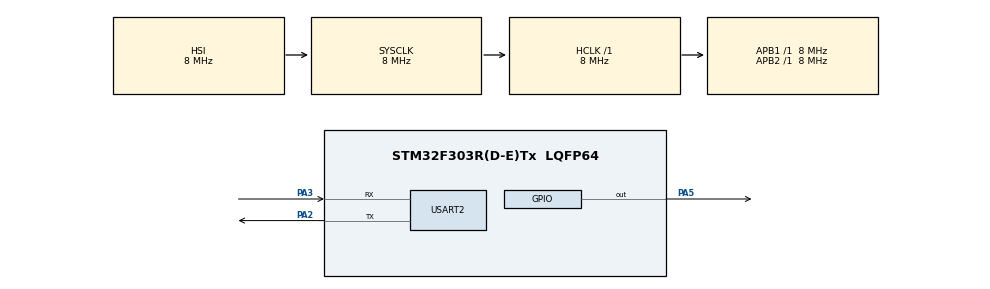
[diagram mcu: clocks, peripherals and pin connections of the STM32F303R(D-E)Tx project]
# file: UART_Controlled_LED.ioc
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Mcu.Family=STM32F3
Mcu.Name=STM32F303R(D-E)Tx
Mcu.Package=LQFP64
NVIC.PriorityGroup=NVIC_PRIORITYGROUP_4
NVIC.USART2_IRQn=true\:0\:0\:false\:false\:true\:true\:true\:true
PA2.Mode=Asynchronous
PA2.Signal=USART2_TX
PA3.Mode=Asynchronous
PA3.Signal=USART2_RX
PA5.Signal=GPIO_Output
ProjectManager.HeapSize=0x200
ProjectManager.StackSize=0x400
ProjectManager.TargetToolchain=STM32CubeIDE
RCC.AHBFreq_Value=8000000
RCC.APB1Freq_Value=8000000
RCC.APB2Freq_Value=8000000
RCC.CortexFreq_Value=8000000
RCC.HSE_VALUE=8000000
RCC.HSI_VALUE=8000000
RCC.LSE_VALUE=32768
RCC.SYSCLKFreq_VALUE=8000000
RCC.USBFreq_Value=16000000
USART2.VirtualMode-Asynchronous=VM_ASYNC
board=custom

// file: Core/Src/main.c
/* USER CODE BEGIN Header */
/**
  ******************************************************************************
  * @file           : main.c
  * @brief          : Main program body
  ******************************************************************************
  * @attention
  *
  * Copyright (c) 2025 STMicroelectronics.
  * All rights reserved.
  *
  * This software is licensed under terms that can be found in the LICENSE file
  * in the root directory of this software component.
  * If no LICENSE file comes with this software, it is provided AS-IS.
  *
  ******************************************************************************
  */
/* USER CODE END Header */
#include "main.h"

/* USER CODE BEGIN Includes */
#include "stdio.h"
#include <string.h>
#include <stdbool.h>
/* USER CODE END Includes */

UART_HandleTypeDef huart2;

void SystemClock_Config(void);
static void MX_GPIO_Init(void);
static void MX_USART2_UART_Init(void);

/* USER CODE BEGIN 0 */
/*volatile uint8_t RxByte = 0;
volatile uint8_t RxBuffer[3];
volatile uint8_t indx = 0;
volatile uint8_t command_ready = 0;
void HAL_UART_RxCpltCallback(UART_HandleTypeDef *huart)
{

	if (huart->Instance == USART2)
	    {
	        RxBuffer[indx++] = RxByte;

	        if (RxByte == '\n' || RxByte == '\r'|| indx >= sizeof(RxBuffer))
	        {
	            HAL_UART_Transmit(&huart2, (uint8_t *)RxBuffer, indx, HAL_MAX_DELAY);
	            indx = 0;
	            command_ready=1;
	        }
	        HAL_UART_Receive_IT(&huart2, (uint8_t *)&RxByte, 1);
	    }
}*/
#define RX_BUFFER_SIZE 10
char rxBuffer[RX_BUFFER_SIZE];
int rxIndex = 0;
char *msg;
/* USER CODE END 0 */

int main(void)
{

  /* MCU Configuration--------------------------------------------------------*/

  /* Reset of all peripherals, Initializes the Flash interface and the Systick. */
  HAL_Init();

  /* Configure the system clock */
  SystemClock_Config();

  /* Initialize all configured peripherals */
  MX_GPIO_Init();
  MX_USART2_UART_Init();
  /* USER CODE BEGIN 2 */
  /*printf("Enter the command to turn on LED on or off:\n");
  HAL_UART_Receive_IT(&huart2, (uint8_t *)&RxByte, 1);*/

    /* USER CODE END 2 */

  /* Infinite loop */
  while (1)
  {
	    /*if (command_ready)
	    {
	        HAL_UART_Transmit(&huart2, (uint8_t *)"\nCMD: ", 6, HAL_MAX_DELAY);
	        HAL_UART_Transmit(&huart2, (uint8_t *)RxBuffer, strlen((char*)RxBuffer), HAL_MAX_DELAY);
	        HAL_UART_Transmit(&huart2, (uint8_t *)"\r\n", 2, HAL_MAX_DELAY);
	      if (strcmp((char *)RxBuffer, "on") == 0)
	      {
	        HAL_GPIO_WritePin(GPIOA, GPIO_PIN_5, GPIO_PIN_SET);
	        char *msg = "LED turned ON\r\n";
	        HAL_UART_Transmit(&huart2, (uint8_t *)msg, strlen(msg), HAL_MAX_DELAY);
	      }
	      else if (strcmp((char *)RxBuffer, "off") == 0)
	      {
	        HAL_GPIO_WritePin(GPIOA, GPIO_PIN_5, GPIO_PIN_RESET);
	        char *msg = "LED turned OFF\r\n";
	        HAL_UART_Transmit(&huart2, (uint8_t *)msg, strlen(msg), HAL_MAX_DELAY);
	      }
	      else
	      {
	        char *msg = "Invalid command\r\n";
	        HAL_UART_Transmit(&huart2, (uint8_t *)msg, strlen(msg), HAL_MAX_DELAY);
	      }

	      command_ready = 0;  // reset flag after processing
	    }*/
	  uint8_t received_char;
	      // Receive one byte at a time (blocking)
	      HAL_UART_Receive(&huart2, &received_char, 1, HAL_MAX_DELAY);

	      if (received_char == '\r' || received_char == '\n')
	      {
	          rxBuffer[rxIndex] = '\0';  // Null-terminate the string
	          rxIndex = 0;               // Reset index for next command

	          if (strcmp(rxBuffer, "on") == 0)
	          {
	              HAL_GPIO_WritePin(GPIOA, GPIO_PIN_5, GPIO_PIN_SET);
	              msg = "LED turned ON\r\n";
	          }
	          else if (strcmp(rxBuffer, "off") == 0)
	          {
	              HAL_GPIO_WritePin(GPIOA, GPIO_PIN_5, GPIO_PIN_RESET);
	              msg = "LED turned OFF\r\n";
	          }
	          else
	          {
	              msg = "Invalid command. Type 'on' or 'off'.\r\n";
	          }

	          HAL_UART_Transmit(&huart2, (uint8_t*)msg, strlen(msg), HAL_MAX_DELAY);
	      }
	      else
	      {
	          if (rxIndex < RX_BUFFER_SIZE - 1)
	          {
	              rxBuffer[rxIndex++] = received_char;
	          }
	          // else: input too long, could reset rxIndex or handle error
	      }
  }
}

void SystemClock_Config(void)
{
  RCC_OscInitTypeDef RCC_OscInitStruct = {0};
  RCC_ClkInitTypeDef RCC_ClkInitStruct = {0};
  RCC_PeriphCLKInitTypeDef PeriphClkInit = {0};

  /** Initializes the RCC Oscillators according to the specified parameters
  * in the RCC_OscInitTypeDef structure.
  */
  RCC_OscInitStruct.OscillatorType = RCC_OSCILLATORTYPE_HSI;
  RCC_OscInitStruct.HSIState = RCC_HSI_ON;
  RCC_OscInitStruct.HSICalibrationValue = RCC_HSICALIBRATION_DEFAULT;
  RCC_OscInitStruct.PLL.PLLState = RCC_PLL_NONE;
  if (HAL_RCC_OscConfig(&RCC_OscInitStruct) != HAL_OK)
  {
    Error_Handler();
  }

  /** Initializes the CPU, AHB and APB buses clocks
  */
  RCC_ClkInitStruct.ClockType = RCC_CLOCKTYPE_HCLK|RCC_CLOCKTYPE_SYSCLK
                              |RCC_CLOCKTYPE_PCLK1|RCC_CLOCKTYPE_PCLK2;
  RCC_ClkInitStruct.SYSCLKSource = RCC_SYSCLKSOURCE_HSI;
  RCC_ClkInitStruct.AHBCLKDivider = RCC_SYSCLK_DIV1;
  RCC_ClkInitStruct.APB1CLKDivider = RCC_HCLK_DIV1;
  RCC_ClkInitStruct.APB2CLKDivider = RCC_HCLK_DIV1;

  if (HAL_RCC_ClockConfig(&RCC_ClkInitStruct, FLASH_LATENCY_0) != HAL_OK)
  {
    Error_Handler();
  }
  PeriphClkInit.PeriphClockSelection = RCC_PERIPHCLK_USART2;
  PeriphClkInit.Usart2ClockSelection = RCC_USART2CLKSOURCE_PCLK1;
  if (HAL_RCCEx_PeriphCLKConfig(&PeriphClkInit) != HAL_OK)
  {
    Error_Handler();
  }
}

static void MX_USART2_UART_Init(void)
{

  huart2.Instance = USART2;
  huart2.Init.BaudRate = 115200;
  huart2.Init.WordLength = UART_WORDLENGTH_8B;
  huart2.Init.StopBits = UART_STOPBITS_1;
  huart2.Init.Parity = UART_PARITY_NONE;
  huart2.Init.Mode = UART_MODE_TX_RX;
  huart2.Init.HwFlowCtl = UART_HWCONTROL_NONE;
  huart2.Init.OverSampling = UART_OVERSAMPLING_16;
  huart2.Init.OneBitSampling = UART_ONE_BIT_SAMPLE_DISABLE;
  huart2.AdvancedInit.AdvFeatureInit = UART_ADVFEATURE_NO_INIT;
  if (HAL_UART_Init(&huart2) != HAL_OK)
  {
    Error_Handler();
  }

}

static void MX_GPIO_Init(void)
{
  GPIO_InitTypeDef GPIO_InitStruct = {0};

  /* GPIO Ports Clock Enable */
  __HAL_RCC_GPIOA_CLK_ENABLE();

  /*Configure GPIO pin Output Level */
  HAL_GPIO_WritePin(GPIOA, GPIO_PIN_5, GPIO_PIN_RESET);

  /*Configure GPIO pin : PA5 */
  GPIO_InitStruct.Pin = GPIO_PIN_5;
  GPIO_InitStruct.Mode = GPIO_MODE_OUTPUT_PP;
  GPIO_InitStruct.Pull = GPIO_NOPULL;
  GPIO_InitStruct.Speed = GPIO_SPEED_FREQ_LOW;
  HAL_GPIO_Init(GPIOA, &GPIO_InitStruct);

}

void Error_Handler(void)
{
  __disable_irq();
  while (1)
  {
  }
}
